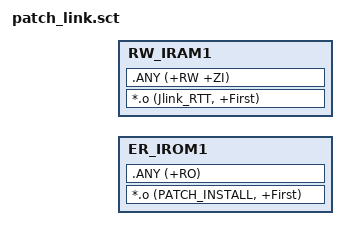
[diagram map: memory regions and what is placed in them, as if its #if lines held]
#! armclang -E --target=arm-arm-none-eabi -mcpu=cortex-m33 -xc
#include "../../../../../../drivers/cmsis/sf32lb55x/mem_map.h"
#include "../../rtconfig.h"

; *************************************************************
; *** Scatter-Loading Description File generated by uVision ***
; *************************************************************

LR_IROM1 BOOTLOADER_PATCH_CODE_ADDR BOOTLOADER_PATCH_CODE_SIZE  {    ; load region size_region, 
  ER_IROM1 BOOTLOADER_PATCH_CODE_ADDR BOOTLOADER_PATCH_CODE_SIZE  {  ; load address = execution address
  	*.o (PATCH_INSTALL, +First)
   	.ANY (+RO)
  }
  RW_IRAM1 BOOTLOADER_PATCH_DATA_ADDR BOOTLOADER_PATCH_DATA_SIZE  {  ; RW data
#ifdef BSP_USING_JLINK_RTT    
   *.o (Jlink_RTT, +First)
#endif   
   .ANY (+RW +ZI)
  }
}
